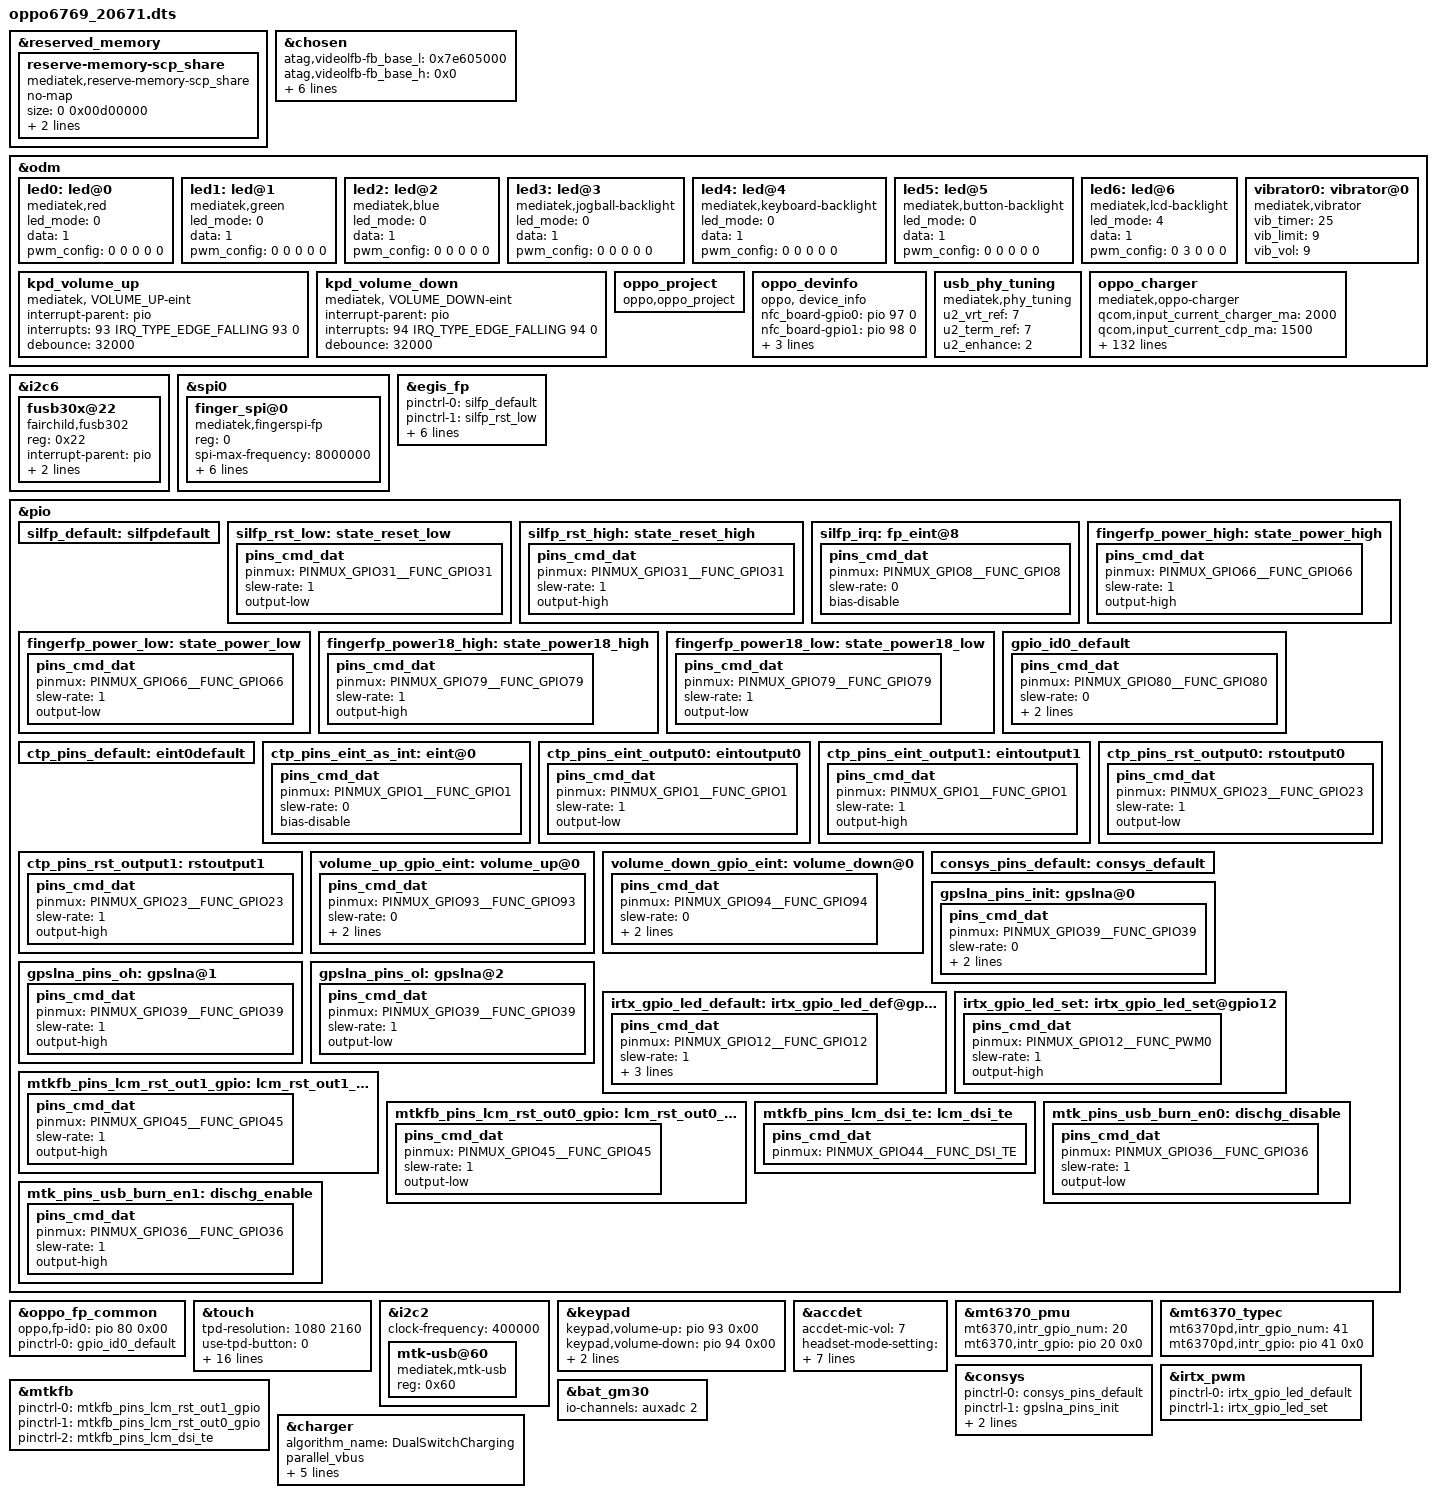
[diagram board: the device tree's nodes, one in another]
/*
 * Copyright (C) 2019 MediaTek Inc.
 *
 * This program is free software; you can redistribute it and/or modify
 * it under the terms of the GNU General Public License version 2 as
 * published by the Free Software Foundation.
 *
 * This program is distributed in the hope that it will be useful,
 * but WITHOUT ANY WARRANTY; without even the implied warranty of
 * MERCHANTABILITY or FITNESS FOR A PARTICULAR PURPOSE.
 * See http://www.gnu.org/licenses/gpl-2.0.html for more details.
 */

/dts-v1/;
/plugin/;
#include <dt-bindings/interrupt-controller/irq.h>
#include <dt-bindings/interrupt-controller/arm-gic.h>
#include <dt-bindings/pinctrl/mt6768-pinfunc.h>

&reserved_memory {
	reserve-memory-scp_share {
		compatible = "mediatek,reserve-memory-scp_share";
		no-map;
		size = <0 0x00d00000>;
		alignment = <0 0x1000000>;
		alloc-ranges = <0 0x40000000 0 0x50000000>;
	};
};

/* chosen */
&chosen {

	atag,videolfb-fb_base_l = <0x7e605000>;
	atag,videolfb-fb_base_h = <0x0>;
	atag,videolfb-islcmfound = <1>;
	atag,videolfb-islcm_inited = <0>;
	atag,videolfb-fps= <6000>;
	atag,videolfb-vramSize= <0x017e8000>;
	atag,videolfb-lcmname=
		"hx83112b_fhdp_dsi_cmd_auo_rt5081_drv";
};

&odm {
	led0:led@0 {
		compatible = "mediatek,red";
		led_mode = <0>;
		data = <1>;
		pwm_config = <0 0 0 0 0>;
	};
	led1:led@1 {
		compatible = "mediatek,green";
		led_mode = <0>;
		data = <1>;
		pwm_config = <0 0 0 0 0>;
	};
	led2:led@2 {
		compatible = "mediatek,blue";
		led_mode = <0>;
		data = <1>;
		pwm_config = <0 0 0 0 0>;
	};
	led3:led@3 {
		compatible = "mediatek,jogball-backlight";
		led_mode = <0>;
		data = <1>;
		pwm_config = <0 0 0 0 0>;
	};
	led4:led@4 {
		compatible = "mediatek,keyboard-backlight";
		led_mode = <0>;
		data = <1>;
		pwm_config = <0 0 0 0 0>;
	};
	led5:led@5 {
		compatible = "mediatek,button-backlight";
		led_mode = <0>;
		data = <1>;
		pwm_config = <0 0 0 0 0>;
	};
	led6:led@6 {
		compatible = "mediatek,lcd-backlight";
                //#ifndef ODM_HQ_EDIT
                //liyan@ODM.Multimedia.LCD  2019/08/27 modify for lcd-bl mode
                //led_mode = <5>;
                //#else
                led_mode = <4>;
                //#endif
		data = <1>;
		pwm_config = <0 3 0 0 0>;
	};
	vibrator0:vibrator@0 {
		compatible = "mediatek,vibrator";
		vib_timer = <25>;
		vib_limit = <9>;
		vib_vol= <9>;
	};
//#ifdef VENDOR_EDIT
	//#ifdef ODM_HQ_EDIT
	/* sunjingtao@EXP.BSP.bootloader.bootflow, 2019/10/26, add for keypad volume up and volume down */
	kpd_volume_up:kpd_volume_up {
               compatible = "mediatek, VOLUME_UP-eint";
               interrupt-parent = <&pio>;
               interrupts = <93 IRQ_TYPE_EDGE_FALLING 93 0>;
               debounce = <32000>;
               status = "okay";
       };

	kpd_volume_down:kpd_volume_down {
			compatible = "mediatek, VOLUME_DOWN-eint";
			interrupt-parent = <&pio>;
			interrupts = <94 IRQ_TYPE_EDGE_FALLING 94 0>;
			debounce = <32000>;
			status = "okay";
	};
	//#endif // ODM_HQ_EDIT
/*Bin.Li@EXP.BSP.bootloader.bootflow, 2017/05/15, Add for oppo project */
	oppo_project:oppo_project {
		compatible = "oppo,oppo_project";
	};
//#endif /*VENDOR_EDIT*/

//#ifdef ODM_HQ_EDIT
//sunjingtao@ODM.BSP.bootloader, 2019/10/17, Add for oppo project
	oppo_devinfo:oppo_devinfo {
		compatible = "oppo, device_info";
		nfc_board-gpio0 = <&pio 97 0>;
		nfc_board-gpio1 = <&pio 98 0>;
		nfc_board-gpio2 = <&pio 21 0>;
		sub_board-gpio = <&pio 30 0>;
		sdcard-gpio = <&pio 18 0>;
	};
//endif

//#ifdef ODM_HQ_EDIT
/*zhangchao@ODM_HQ.BSP.CHG 2020/03/16,modify usb eye parameter*/
	usb_phy_tuning {
		compatible = "mediatek,phy_tuning";
		u2_vrt_ref = <7>;
		u2_term_ref = <7>;
		u2_enhance = <2>;
	};
//#endif

//#ifdef ODM_HQ_EDIT
/*wangtao@ODM_HQ.BSP.CHG 2020/02/26,bring up charge*/
	oppo_charger: oppo_charger {
		compatible = "mediatek,oppo-charger";
		//pinctrl-names = "default", "charger_gpio_as_output_low", "charger_gpio_as_output_high", "ship_sleep", "ship_active", "shortc_active";
		//pinctrl-0 = <&charger_pins_default>;
		//pinctrl-1 = <&charger_pins_eint_output0>;
		//pinctrl-2 = <&charger_pins_eint_output1>;
		//pinctrl-3 = <&ship_sleep_gpio>;
		//pinctrl-4 = <&ship_active_gpio>;
		//pinctrl-5 = <&shortc_active_gpio>;

		//for oppo chg framework:
		qcom,input_current_charger_ma = <2000>;
		qcom,input_current_cdp_ma = <1500>;
		qcom,input_current_usb_ma = <500>;
		qcom,input_current_led_ma = <1200>;
		qcom,input_current_led_ma_forcmcc = <500>;
		qcom,input_current_camera_ma = <1200>;
		qcom,input_current_calling_ma = <1200>;
		
		qcom,input_current_led_ma_high = <1000>;
		qcom,input_current_led_ma_warm = <1500>;
		qcom,input_current_led_ma_normal = <2000>;

		qcom,led_high_bat_decidegc = <370>;
		qcom,led_warm_bat_decidegc = <340>;

		qcom,iterm_disabled = <0>;
		qcom,iterm_ma = <265>;
		qcom,recharge-mv = <115>;

		qcom,batt_capacity_mah = <5000>; /*typical capacity*/
		//qcom,batt_capacity_mah = <3900>; /*rated capacity*/

		qcom,removed_bat_decidegc = <190>;  /* < -19C */

		qcom,cold_bat_decidegc = <20>;  /* -2C ~ 0C */
		qcom,temp_cold_vfloat_mv = <3980>;
		qcom,temp_cold_fastchg_current_ma = <350>;

		qcom,little_cold_bat_decidegc = <0>;	/* 0C ~ 5C */
		qcom,temp_little_cold_vfloat_mv = <4435>;
		qcom,temp_little_cold_fastchg_current_ma_high = <650>;
		qcom,temp_little_cold_fastchg_current_ma_low = <650>;
		qcom,temp_little_cold_fastchg_current_ma = <650>;
		monet,temp_little_cold_usbchg_current_ma_high = <650>;
		monet,temp_little_cold_usbchg_current_ma_low = <650>;
		monet,temp_little_cold_usbchg_current_ma = <650>;

		qcom,cool_bat_decidegc = <50>;	/* 5C ~ 12C */
		qcom,temp_cool_vfloat_mv = <4435>;
		qcom,temp_cool_fastchg_current_ma_high = <1350>;
		qcom,temp_cool_fastchg_current_ma_low = <650>;
		monet,temp_cool_usbchg_current_ma_high = <650>;
		monet,temp_cool_usbchg_current_ma_low = <550>;

		qcom,little_cool_bat_decidegc = <120>;	/* 12C ~ 16C */
		qcom,temp_little_cool_vfloat_mv = <4435>;
		qcom,temp_little_cool_fastchg_current_ma = <2050>;
		monet,temp_little_cool_usbchg_current_ma = <550>;

		qcom,normal_bat_decidegc = <160>;	/* 16C ~ 45C */
		qcom,temp_normal_fastchg_current_ma = <3600>;
		monet,temp_normal_usbchg_current_ma = <550>;
		qcom,temp_normal_vfloat_mv = <4435>;

		qcom,warm_bat_decidegc = <450>;		/* 45C ~ 53C */ /*8pin Bat Vooc project need add 3 degree C*/
		qcom,temp_warm_vfloat_mv = <4130>;
		qcom,temp_warm_fastchg_current_ma = <1350>;
		monet,temp_warm_usbchg_current_ma = <550>;
		qcom,temp_warm_fastchg_current_ma_led_on = <500>;

		qcom,hot_bat_decidegc = <530>;  /* > 53C */

		qcom,non_standard_vfloat_mv = <3980>;
		qcom,non_standard_fastchg_current_ma = <512>;

		qcom,short_c_bat_cv_mv = <4330>;
		qcom,short_c_bat_vfloat_mv = <3800>;
		qcom,short_c_bat_fastchg_current_ma = <512>;
		qcom,short_c_bat_vfloat_sw_limit = <3750>;

		qcom,cold_vfloat_sw_limit = <3930>;
		qcom,little_cold_vfloat_sw_limit = <4380>;
		qcom,cool_vfloat_sw_limit = <4380>;
		qcom,little_cool_vfloat_sw_limit = <4380>;
		qcom,normal_vfloat_sw_limit = <4380>;
		qcom,warm_vfloat_sw_limit = <4080>;
		qcom,non_standard_vfloat_sw_limit = <3930>;

		qcom,max_chg_time_sec = <36000>;
		qcom,charger_hv_thr = <9800>;
		qcom,charger_recv_thr = <9800>;
		qcom,charger_lv_thr = <3400>;
		qcom,vbatt_full_thr = <4400>;
		qcom,vbatt_hv_thr = <4550>;

		qcom,vfloat_step_mv = <10>;
		qcom,non_standard_vfloat_over_sw_limit = <4000>;
		qcom,cold_vfloat_over_sw_limit = <4000>;
		qcom,little_cold_vfloat_over_sw_limit = <4450>;
		qcom,cool_vfloat_over_sw_limit = <4450>;
		qcom,little_cool_vfloat_over_sw_limit = <4450>;
		qcom,normal_vfloat_over_sw_limit = <4450>;
		qcom,warm_vfloat_over_sw_limit = <4150>;

		qcom,vbatt_power_off = <3300>;
		qcom,vbatt_soc_1 = <3410>;
		qcom,vooc_project = <0>;
		qcom,vbatt_num = <1>;

		qcom,normal_vterm_hw_inc = <150>;
		qcom,non_normal_vterm_hw_inc = <10>;

		qcom,ff1_normal_fastchg_ma = <1088>;
		qcom,ffc2_normal_fastchg_ma = <780>;/*16C~35c*/
		qcom,ffc2_temp_warm_decidegc = <350>;
		qcom,ffc2_warm_fastchg_ma = <840>;/*35C~40c*/
		qcom,ffc2_temp_high_decidegc = <400>;
		qcom,ffc2_temp_low_decidegc = <120>;
		qcom,ff1_exit_step_ma = <488>;
		qcom,ff1_warm_exit_step_ma = <418>;
		qcom,ffc2_exit_step_ma = <180>;
		qcom,ffc2_warm_exit_step_ma = <170>;

		qcom,ffc_normal_vfloat_sw_limit = <4430>;
		qcom,ffc_temp_normal_vfloat_mv = <4500>;
		qcom,ffc_normal_vfloat_over_sw_limit = <4500>;

		qcom,default_iterm_ma = <265>;
		qcom,default_temp_normal_fastchg_current_ma = <3600>;
		qcom,default_normal_vfloat_sw_limit = <4380>;
		qcom,default_temp_normal_vfloat_mv = <4435>;
		qcom,default_normal_vfloat_over_sw_limit = <4450>;

		//for 2nd chip:
		qcom,iterm_ma_2nd = <300>;
		qcom,recharge-mv_2nd = <121>;

		qcom,temp_little_cold_vfloat_mv_2nd = <4391>;	/* 0C ~ 5C */
		qcom,temp_cool_vfloat_mv_2nd = <4391>;	/* 5C ~ 12C */
		qcom,temp_little_cool_vfloat_mv_2nd = <4391>;	/* 12C ~ 16C */
		qcom,temp_normal_vfloat_mv_2nd = <4391>;	/* 16C ~ 45C */

		qcom,little_cold_vfloat_over_sw_limit_2nd = <4395>;
		qcom,cool_vfloat_over_sw_limit_2nd = <4395>;
		qcom,little_cool_vfloat_over_sw_limit_2nd = <4395>;
		qcom,normal_vfloat_over_sw_limit_2nd = <4395>;

		qcom,default_iterm_ma_2nd = <300>;
		qcom,default_temp_normal_vfloat_mv_2nd = <4391>;
		qcom,default_normal_vfloat_over_sw_limit_2nd = <4395>;

		qcom,pd_input_current_charger_ma = <3300>;
		qcom,pd_temp_normal_fastchg_current_ma = <3300>;
		qcom,qc_temp_normal_fastchg_current_ma = <3400>;
		qcom,qc_input_current_charger_ma = <3400>;

		//for control:
		//qcom,suspend_after_full;
		qcom,check_batt_full_by_sw;
		//qcom,external_gauge;
		qcom,chg_ctrl_by_calling;
		qcom,chg_ctrl_by_lcd;
		qcom,chg_ctrl_by_camera;
		qcom,sw_vfloat_over_protect_enable;
		//qcom,ffc_support;

		//GPIO config:
		//qcom,chargerid_switch-gpio = <&pio 97 0x00>;
		//qcom,ship-gpio = <&pio 155 0x00>;
		//qcom,shortc-gpio = <&pio 77 0x00>;

		qcom,vbatt_pdqc_to_5v_thr = <4420>;

		io-channels = <&auxadc 3>, <&auxadc 4>;
		io-channel-names = "usbtemp-ch3", "usbtemp-ch4";

		qcom,dischg-gpio = <&pio 36 0x00>;
		pinctrl-names = "dischg_disable", "dischg_enable";
		pinctrl-0 = <&mtk_pins_usb_burn_en0>;
		pinctrl-1 = <&mtk_pins_usb_burn_en1>;
		status = "okay";
	};
//#endif
};

//#ifdef ODM_HQ_EDIT
//zhangchao@ODM_HQ.BSP.CHG 2020/03/12,charger bring up fusb30b
&i2c6 {
	fusb30x@22 {
		status = "ok";
		compatible = "fairchild,fusb302";
		reg = <0x22>;
		interrupt-parent = <&pio>;
		interrupts = <41 0x2>;
		fairchild,int_n = <&pio 41 0>;
	};
};
//#endif

//#ifdef VENDOR_EDIT
//Qingwen.Liu@RM.BSP.Fingerprint.Basic 2019/1/26 add for fpc fingerprint driver start
&spi0 {
	#address-cells = <1>;
	#size-cells = <0>;
	status = "okay";
	finger_spi@0 {
	    compatible = "mediatek,fingerspi-fp";
	    reg = <0>;
	    spi-max-frequency = <8000000>;
	    netlink-event = <30>;
	    spi-id = <0>;
	    spi-irq = <31>;
	    spi-reg = <0x1100a000>;
	    spi-avdd-gpio = <66>;
	    spi-avdd18-gpio = <79>;
        status = "okay";
    };
};

&egis_fp {
	pinctrl-names = "default", "rst-low", "rst-high",
	                "irq-init", "power_high","power_low", "power18_high","power18_low";
	pinctrl-0 = <&silfp_default>;
	pinctrl-1 = <&silfp_rst_low>;
	pinctrl-2 = <&silfp_rst_high>;
	pinctrl-3 = <&silfp_irq>;
	pinctrl-4 = <&fingerfp_power_high>;
	pinctrl-5 = <&fingerfp_power_low>;
	pinctrl-6 = <&fingerfp_power18_high>;
	pinctrl-7 = <&fingerfp_power18_low>;
	status = "okay";
};

&pio {
	silfp_default: silfpdefault {
	};
	silfp_rst_low: state_reset_low {
		pins_cmd_dat {
			pinmux = <PINMUX_GPIO31__FUNC_GPIO31>;
			slew-rate = <1>;
			output-low;
		};
	};
	silfp_rst_high: state_reset_high {
		pins_cmd_dat {
			pinmux = <PINMUX_GPIO31__FUNC_GPIO31>;
			slew-rate = <1>;
			output-high;
		};
	};
	silfp_irq: fp_eint@8 {
		pins_cmd_dat {
			pinmux = <PINMUX_GPIO8__FUNC_GPIO8>;
			slew-rate = <0>;
			bias-disable;
		};
	};
	fingerfp_power_high: state_power_high {
		pins_cmd_dat {
			pinmux = <PINMUX_GPIO66__FUNC_GPIO66>;
			slew-rate = <1>;
			output-high;
		};
	};

	fingerfp_power_low: state_power_low {
		pins_cmd_dat {
			pinmux = <PINMUX_GPIO66__FUNC_GPIO66>;
			slew-rate = <1>;
			output-low;
		};
	};
	fingerfp_power18_high: state_power18_high {
		pins_cmd_dat {
			pinmux = <PINMUX_GPIO79__FUNC_GPIO79>;
			slew-rate = <1>;
			output-high;
		};
	};

	fingerfp_power18_low: state_power18_low {
		pins_cmd_dat {
			pinmux = <PINMUX_GPIO79__FUNC_GPIO79>;
			slew-rate = <1>;
			output-low;
		};
	};
};

/*the id config to project dts.*/
&pio{
	gpio_id0_default: gpio_id0_default {
		pins_cmd_dat {
			pinmux = <PINMUX_GPIO80__FUNC_GPIO80>;
			slew-rate = <0>;
			bias-pull-up = <00>;
			input-enable;
		};
	};
};

&oppo_fp_common {
	oppo,fp-id0 = <&pio 80 0x00>;
	pinctrl-names = "default";
	pinctrl-0 = <&gpio_id0_default>;
};
//Qingwen.Liu@RM.BSP.Fingerprint.Basic 2019/1/26 add for fpc fingerprint driver end
//#endif //VENDOR_EDIT
/* TOUCH start */
&touch {
	tpd-resolution = <1080 2160>;
	use-tpd-button = <0>;
	tpd-key-num = <3>;
	tpd-key-local= <139 172 158 0>;
	tpd-key-dim-local = <90 883 100 40 230
				883 100 40 370 883 100 40 0 0 0 0>;
	tpd-max-touch-num = <10>;
	tpd-filter-enable = <1>;
	tpd-filter-pixel-density = <168>;
	tpd-filter-custom-prameters = <0 0 0 0 0 0 0 0 0 0 0 0>;
	tpd-filter-custom-speed = <0 0 0>;
	pinctrl-names = "default", "state_eint_as_int",
		"state_eint_output0", "state_eint_output1",
		"state_rst_output0", "state_rst_output1";
	pinctrl-0 = <&ctp_pins_default>;
	pinctrl-1 = <&ctp_pins_eint_as_int>;
	pinctrl-2 = <&ctp_pins_eint_output0>;
	pinctrl-3 = <&ctp_pins_eint_output1>;
	pinctrl-4 = <&ctp_pins_rst_output0>;
	pinctrl-5 = <&ctp_pins_rst_output1>;
	status = "okay";
};
&pio {
	ctp_pins_default: eint0default {
	};
	ctp_pins_eint_as_int: eint@0 {
		pins_cmd_dat {
			pinmux = <PINMUX_GPIO1__FUNC_GPIO1>;
			slew-rate = <0>;
			bias-disable;
		};
	};
	ctp_pins_eint_output0: eintoutput0 {
		pins_cmd_dat {
			pinmux = <PINMUX_GPIO1__FUNC_GPIO1>;
			slew-rate = <1>;
			output-low;
		};
	};
	ctp_pins_eint_output1: eintoutput1 {
		pins_cmd_dat {
			pinmux = <PINMUX_GPIO1__FUNC_GPIO1>;
			slew-rate = <1>;
			output-high;
	};
	};
	ctp_pins_rst_output0: rstoutput0 {
		pins_cmd_dat {
			pinmux = <PINMUX_GPIO23__FUNC_GPIO23>;
			slew-rate = <1>;
			output-low;
		};
	};
	ctp_pins_rst_output1: rstoutput1 {
		pins_cmd_dat {
			pinmux = <PINMUX_GPIO23__FUNC_GPIO23>;
			slew-rate = <1>;
			output-high;
		};
	};
};
/* TOUCH end */

&i2c2 {
	clock-frequency = <400000>;

	mtk-usb@60 {
		compatible = "mediatek,mtk-usb";
		reg = <0x60>;
		status = "okay";
	};
};

//#ifdef ODM_HQ_EDIT
/* sunjingtao@EXP.BSP.bootloader.bootflow, 2019/10/26, add for keypad volume up and volume down */
&keypad {
	keypad,volume-up	= <&pio 93 0x00>;
	keypad,volume-down	= <&pio 94 0x00>;
	pinctrl-names = "volume_up_as_int", "volume_down_as_int";
	pinctrl-0 = <&volume_up_gpio_eint>;
	pinctrl-1 = <&volume_down_gpio_eint>;
	status = "okay";
};

&pio {
	volume_up_gpio_eint:volume_up@0{
		pins_cmd_dat {
			pinmux = <PINMUX_GPIO93__FUNC_GPIO93>;
			slew-rate = <0>;  /*direction 0:in, 1:out*/
			bias-pull-up = <00>;
			input-enable;
		};
	};
	volume_down_gpio_eint:volume_down@0{
		pins_cmd_dat {
			pinmux = <PINMUX_GPIO94__FUNC_GPIO94>;
			slew-rate = <0>;  /*direction 0:in, 1:out*/
			bias-pull-up = <01>;
			input-enable;
		};
	};
};
//#endif /*ODM_HQ_EDIT*/
/* accdet start  */
&accdet {
	/* accdet micbias voltage: 0x07,2.7v;0x05,2.5v;0x02,1.9v */
	//sunjingtao@ODM.HQ.Multimedia.Audio 2020/03/18 modified for micbias1
	accdet-mic-vol = <7>;
	headset-mode-setting = <0x500 0x500 1 0x1f0 0x800 0x800 0x20 0x44>;
	accdet-plugout-debounce = <1>;
	/*1:ACC mode, 2:low cost without in bias, 6:low cost with in bias*/
	accdet-mic-mode = <1>;
	/* eint_level_trigger: 8,LEVEL_LOW(DEF) ;4,LV_HIGH;others,LV_LOW */
	headset-eint-level-pol = <8>;
	/*0--MD_MAX--UP_MAX--DW_MAX*/
	headset-three-key-threshold = <0 80 220 400>;
	headset-three-key-threshold-CDD = <0 121 192 600>;
	/*0--MD_MAX--VOICE_MAX--UP_MAX--DW_MAX*/
	headset-four-key-threshold = <0 58 121 192 400>;
	status = "okay";
};
/* accdet end */

&mt6370_pmu {
	mt6370,intr_gpio_num = <20>; /* direct defined GPIO num */
	mt6370,intr_gpio = <&pio 20 0x0>;
};
&mt6370_typec {
	mt6370pd,intr_gpio_num = <41>; /* direct defined GPIO num */
	mt6370pd,intr_gpio = <&pio 41 0x0>;
};

/* CONSYS GPIO standardization */
&pio {
	consys_pins_default: consys_default {
	};
	gpslna_pins_init: gpslna@0 {
		pins_cmd_dat {
			pinmux = <PINMUX_GPIO39__FUNC_GPIO39>;
			slew-rate = <0>;
			bias-disable;
			output-low;
		};
	};
	gpslna_pins_oh: gpslna@1 {
		pins_cmd_dat {
			pinmux = <PINMUX_GPIO39__FUNC_GPIO39>;
			slew-rate = <1>;
			output-high;
		};
	};
	gpslna_pins_ol: gpslna@2 {
		pins_cmd_dat {
			pinmux = <PINMUX_GPIO39__FUNC_GPIO39>;
			slew-rate = <1>;
			output-low;
		};
	};
};
&consys {
	pinctrl-names = "default", "gps_lna_state_init",
		"gps_lna_state_oh", "gps_lna_state_ol";
	pinctrl-0 = <&consys_pins_default>;
	pinctrl-1 = <&gpslna_pins_init>;
	pinctrl-2 = <&gpslna_pins_oh>;
	pinctrl-3 = <&gpslna_pins_ol>;
	status = "okay";
};
/* CONSYS end */

/* IRTX GPIO Start */
&irtx_pwm {
	pinctrl-names = "irtx_gpio_led_default", "irtx_gpio_led_set";
	pinctrl-0 = <&irtx_gpio_led_default>;
	pinctrl-1 = <&irtx_gpio_led_set>;
	status = "okay";
};
&pio {
	/* IRTX GPIO Settings -Start */
	/* default: GPIO0, output, high */
	irtx_gpio_led_default:irtx_gpio_led_def@gpio12 {
		pins_cmd_dat {
			pinmux = <PINMUX_GPIO12__FUNC_GPIO12>;
			slew-rate = <1>;
			bias-disable;
			output-low;
			input-schmitt-enable = <0>;
		};
	};

	irtx_gpio_led_set:irtx_gpio_led_set@gpio12 {
		pins_cmd_dat {
			pinmux = <PINMUX_GPIO12__FUNC_PWM0>;
			slew-rate = <1>;
			output-high;
		};
	};
}; /* IRTX GPIO Settings -End */

/* DISPSYS GPIO standardization */
&pio {
	mtkfb_pins_lcm_rst_out1_gpio: lcm_rst_out1_gpio {
		pins_cmd_dat {
			pinmux = <PINMUX_GPIO45__FUNC_GPIO45>;
			slew-rate = <1>;
			output-high;
		};
	};

	mtkfb_pins_lcm_rst_out0_gpio: lcm_rst_out0_gpio {
		pins_cmd_dat {
			pinmux = <PINMUX_GPIO45__FUNC_GPIO45>;
			slew-rate = <1>;
			output-low;
		};
	};

	mtkfb_pins_lcm_dsi_te: lcm_dsi_te {
		pins_cmd_dat {
			pinmux = <PINMUX_GPIO44__FUNC_DSI_TE>;
		};
	};
};

&mtkfb {
	pinctrl-names =
		"lcm_rst_out1_gpio", "lcm_rst_out0_gpio",
		"mode_te_te";
	pinctrl-0 = <&mtkfb_pins_lcm_rst_out1_gpio>;
	pinctrl-1 = <&mtkfb_pins_lcm_rst_out0_gpio>;
	pinctrl-2 = <&mtkfb_pins_lcm_dsi_te>;
	status = "okay";
};

/* DISPSYS GPIO standardization end*/

/*Tao.Wang@ODM_HQ.BSP.CHG 2020/02/25, charger bringup start*/
&bat_gm30 {
		io-channels = <&auxadc 2>;
		io-channel-names = "batteryID-channel";	
};
&pio {
		mtk_pins_usb_burn_en0: dischg_disable{
                pins_cmd_dat {
                        pinmux = <PINMUX_GPIO36__FUNC_GPIO36>;
                        slew-rate = <1>;
                        output-low;
                };
		};

		mtk_pins_usb_burn_en1: dischg_enable{
                pins_cmd_dat {
                        pinmux = <PINMUX_GPIO36__FUNC_GPIO36>;
                        slew-rate = <1>;
                        output-high;
                };
		};
};

&charger {
	algorithm_name = "DualSwitchCharging";
    parallel_vbus;
	enable_pe_2;
    max_charger_voltage = <15000000>;
	chg1_ta_ac_charger_current = <1800000>;
	chg2_ta_ac_charger_current = <1200000>;
	ac_charger_input_current = <3600000>;
};
#include "bq2589x.dtsi"
#include "bq25910.dtsi"
/*Tao.Wang@ODM_HQ.BSP.CHG 2020/02/25, charger bringup end*/
#include <oppo6769_20671/cust.dtsi>
#include "cust_mt6768_camera.dtsi"
/*End of this file, DO NOT ADD ANYTHING HERE*/
